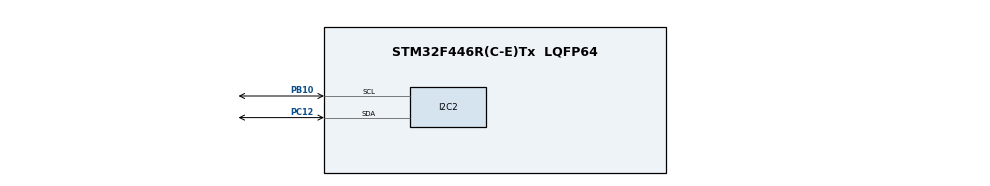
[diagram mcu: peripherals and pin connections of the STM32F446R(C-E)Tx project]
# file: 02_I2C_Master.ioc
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Mcu.Family=STM32F4
Mcu.Name=STM32F446R(C-E)Tx
Mcu.Package=LQFP64
NVIC.PriorityGroup=NVIC_PRIORITYGROUP_4
PB10.Mode=I2C
PB10.Signal=I2C2_SCL
PC12.Mode=I2C
PC12.Signal=I2C2_SDA
ProjectManager.HeapSize=0x200
ProjectManager.StackSize=0x400
ProjectManager.TargetToolchain=STM32CubeIDE
RCC.CortexFreq_Value=16000000
RCC.USBFreq_Value=96000000
RCC.VCOOutputFreq_Value=192000000
board=custom

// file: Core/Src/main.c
/* USER CODE BEGIN Header */
/**
  ******************************************************************************
  * @file           : main.c
  * @brief          : I2C Master Test
  ******************************************************************************
  */
/* USER CODE END Header */

#include "main.h"

I2C_HandleTypeDef hi2c2;

/* USER CODE BEGIN PV */

uint8_t txData[] = "HELLO";

/* USER CODE END PV */

void SystemClock_Config(void);
static void MX_GPIO_Init(void);
static void MX_I2C2_Init(void);

int main(void)
{
  HAL_Init();

  SystemClock_Config();

  MX_GPIO_Init();
  MX_I2C2_Init();

  while (1)
  {
      if (HAL_I2C_IsDeviceReady(
              &hi2c2,
              0x20 << 1,
              3,
              100) == HAL_OK)
      {
          // Slave 발견
          HAL_GPIO_WritePin(GPIOA, GPIO_PIN_5, GPIO_PIN_SET);

          // HELLO 실제 전송
          HAL_I2C_Master_Transmit(
              &hi2c2,
              0x20 << 1,
              txData,
              sizeof(txData),
              100
          );
      }
      else
      {
          // Slave 못 찾음
          HAL_GPIO_WritePin(GPIOA, GPIO_PIN_5, GPIO_PIN_RESET);
      }

      HAL_Delay(1000);
  }
}

void SystemClock_Config(void)
{
  RCC_OscInitTypeDef RCC_OscInitStruct = {0};
  RCC_ClkInitTypeDef RCC_ClkInitStruct = {0};

  __HAL_RCC_PWR_CLK_ENABLE();
  __HAL_PWR_VOLTAGESCALING_CONFIG(PWR_REGULATOR_VOLTAGE_SCALE3);

  RCC_OscInitStruct.OscillatorType = RCC_OSCILLATORTYPE_HSI;
  RCC_OscInitStruct.HSIState = RCC_HSI_ON;
  RCC_OscInitStruct.HSICalibrationValue = RCC_HSICALIBRATION_DEFAULT;
  RCC_OscInitStruct.PLL.PLLState = RCC_PLL_NONE;

  if (HAL_RCC_OscConfig(&RCC_OscInitStruct) != HAL_OK)
  {
    Error_Handler();
  }

  RCC_ClkInitStruct.ClockType =
      RCC_CLOCKTYPE_HCLK |
      RCC_CLOCKTYPE_SYSCLK |
      RCC_CLOCKTYPE_PCLK1 |
      RCC_CLOCKTYPE_PCLK2;

  RCC_ClkInitStruct.SYSCLKSource = RCC_SYSCLKSOURCE_HSI;
  RCC_ClkInitStruct.AHBCLKDivider = RCC_SYSCLK_DIV1;
  RCC_ClkInitStruct.APB1CLKDivider = RCC_HCLK_DIV1;
  RCC_ClkInitStruct.APB2CLKDivider = RCC_HCLK_DIV1;

  if (HAL_RCC_ClockConfig(
          &RCC_ClkInitStruct,
          FLASH_LATENCY_0) != HAL_OK)
  {
    Error_Handler();
  }
}

/**
  * @brief I2C2 Initialization
  */
static void MX_I2C2_Init(void)
{
  hi2c2.Instance = I2C2;

  /* 100 kHz Standard Mode */
  hi2c2.Init.ClockSpeed = 100000;

  hi2c2.Init.DutyCycle = I2C_DUTYCYCLE_2;

  /*
   * Master는 자기 주소가 필요 없으므로 0
   */
  hi2c2.Init.OwnAddress1 = 0;

  hi2c2.Init.AddressingMode = I2C_ADDRESSINGMODE_7BIT;
  hi2c2.Init.DualAddressMode = I2C_DUALADDRESS_DISABLE;
  hi2c2.Init.OwnAddress2 = 0;
  hi2c2.Init.GeneralCallMode = I2C_GENERALCALL_DISABLE;
  hi2c2.Init.NoStretchMode = I2C_NOSTRETCH_DISABLE;

  if (HAL_I2C_Init(&hi2c2) != HAL_OK)
  {
    Error_Handler();
  }
}

/**
  * @brief GPIO Initialization
  */
static void MX_GPIO_Init(void)
{
  GPIO_InitTypeDef GPIO_InitStruct = {0};

  /*
   * GPIO Clock Enable
   *
   * GPIOA : LD2 (PA5)
   * GPIOB : PB10 I2C2_SCL
   * GPIOC : PC12 I2C2_SDA
   */
  __HAL_RCC_GPIOA_CLK_ENABLE();
  __HAL_RCC_GPIOB_CLK_ENABLE();
  __HAL_RCC_GPIOC_CLK_ENABLE();

  /* LD2 초기 상태 OFF */
  HAL_GPIO_WritePin(GPIOA, GPIO_PIN_5, GPIO_PIN_RESET);

  /* PA5 = NUCLEO LD2 */
  GPIO_InitStruct.Pin = GPIO_PIN_5;
  GPIO_InitStruct.Mode = GPIO_MODE_OUTPUT_PP;
  GPIO_InitStruct.Pull = GPIO_NOPULL;
  GPIO_InitStruct.Speed = GPIO_SPEED_FREQ_LOW;

  HAL_GPIO_Init(GPIOA, &GPIO_InitStruct);
}

/**
  * @brief Error Handler
  */
void Error_Handler(void)
{
  __disable_irq();

  while (1)
  {
  }
}
